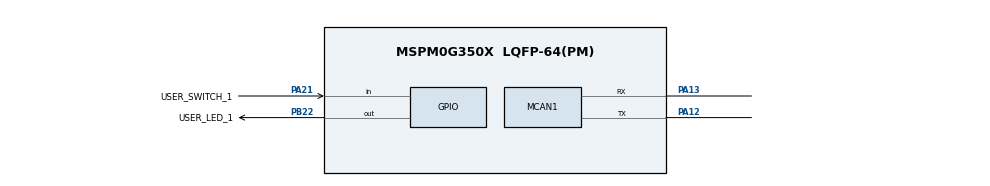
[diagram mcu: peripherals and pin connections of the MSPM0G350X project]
// @cliArgs --device "MSPM0G350X" --package "LQFP-64(PM)" --part "Default"
// @cliArgs --board /ti/boards/LP_MSPM0G3507 --rtos nortos

/**
 * Import the modules used in this configuration.
 */
const GPIO          = scripting.addModule("/ti/driverlib/GPIO", {}, false);
const GPIO1         = GPIO.addInstance();
const GPIO2         = GPIO.addInstance();
const MCAN          = scripting.addModule("/ti/driverlib/MCAN", {}, false);
const MCAN1         = MCAN.addInstance();
const SYSCTL        = scripting.addModule("/ti/driverlib/SYSCTL");
const ProjectConfig = scripting.addModule("/ti/project_config/ProjectConfig");

/**
 * Write custom configuration values to the imported modules.
 */
const mux4       = system.clockTree["EXHFMUX"];
mux4.inputSelect = "EXHFMUX_XTAL";

const pinFunction4        = system.clockTree["HFXT"];
pinFunction4.enable       = true;
pinFunction4.HFXTStartup  = 10;
pinFunction4.HFCLKMonitor = true;
pinFunction4.inputFreq    = 40;

GPIO1.$name                         = "GPIO_LEDS";
GPIO1.port                          = "PORTB";
GPIO1.associatedPins.create(2);
GPIO1.associatedPins[0].$name       = "USER_LED_1";
GPIO1.associatedPins[0].assignedPin = "22";
GPIO1.associatedPins[0].pin.$assign = "PB22";
GPIO1.associatedPins[1].$name       = "USER_LED_2";
GPIO1.associatedPins[1].assignedPin = "27";

const Board = scripting.addModule("/ti/driverlib/Board", {}, false);

GPIO2.$name                         = "GPIO_SWITCHES";
GPIO2.associatedPins[0].$name       = "USER_SWITCH_1";
GPIO2.associatedPins[0].direction   = "INPUT";
GPIO2.associatedPins[0].interruptEn = true;
GPIO2.associatedPins[0].polarity    = "FALL";
GPIO2.associatedPins[0].pin.$assign = "PA21";

MCAN1.$name                    = "MCAN0";
MCAN1.wkupReqEnable            = true;
MCAN1.autoWkupEnable           = true;
MCAN1.emulationEnable          = true;
MCAN1.tdcEnable                = true;
MCAN1.additionalCoreConfig     = true;
MCAN1.rrfe                     = true;
MCAN1.rrfs                     = true;
MCAN1.anfe                     = "1";
MCAN1.anfs                     = "1";
MCAN1.txEventFIFOWaterMark     = 0;
MCAN1.rxFIFO0waterMark         = 0;
MCAN1.enableInterrupt          = true;
MCAN1.interruptLine            = ["DL_MCAN_INTR_LINE_NUM_1"];
MCAN1.interruptLine1Flag       = ["DL_MCAN_INTR_MASK_ALL"];
MCAN1.m0interrupts             = ["DL_MCAN_MSP_INTERRUPT_LINE1"];
MCAN1.overrideRetention        = true;
MCAN1.rxBufElemSize            = "DL_MCAN_ELEM_SIZE_8BYTES";
MCAN1.rxFIFO0ElemSize          = "DL_MCAN_ELEM_SIZE_8BYTES";
MCAN1.rxFIFO1ElemSize          = "DL_MCAN_ELEM_SIZE_8BYTES";
MCAN1.stdFiltType              = "01";
MCAN1.stdFiltElem              = "001";
MCAN1.lss                      = 2;
MCAN1.flesa                    = 0;
MCAN1.lse                      = 0;
MCAN1.interruptFlags           = ["DL_MCAN_INTERRUPT_ARA","DL_MCAN_INTERRUPT_BEU","DL_MCAN_INTERRUPT_BO","DL_MCAN_INTERRUPT_DRX","DL_MCAN_INTERRUPT_ELO","DL_MCAN_INTERRUPT_EP","DL_MCAN_INTERRUPT_EW","DL_MCAN_INTERRUPT_MRAF","DL_MCAN_INTERRUPT_PEA","DL_MCAN_INTERRUPT_PED","DL_MCAN_INTERRUPT_RF0N","DL_MCAN_INTERRUPT_TC","DL_MCAN_INTERRUPT_TEFN","DL_MCAN_INTERRUPT_TOO","DL_MCAN_INTERRUPT_TSW","DL_MCAN_INTERRUPT_WDI"];
MCAN1.stdFiltID1               = 3;
MCAN1.stdFiltID2               = 4;
MCAN1.desiredNomRate           = 1000;
MCAN1.brsEnable                = false;
MCAN1.peripheral.$assign       = "CANFD0";
MCAN1.peripheral.rxPin.$assign = "PA13";
MCAN1.peripheral.txPin.$assign = "PA12";

SYSCTL.CANCLKSource          = "HFCLK";
SYSCTL.useHFCLK_Manual       = true;
SYSCTL.HFCLKSource           = "HFXT";
SYSCTL.HFCLK_Freq            = 48000000;
SYSCTL.HFCLKMonitor          = true;
SYSCTL.HFXTStartup           = 10;
SYSCTL.forceDefaultClkConfig = true;
SYSCTL.clockTreeEn           = true;

ProjectConfig.genLinker = false;
scripting.suppress("All four File Generation options must be enabled in order to guarantee Device Migration support\\. If an option is disabled, the user must manually configure that setting on its own file\\.", ProjectConfig);
